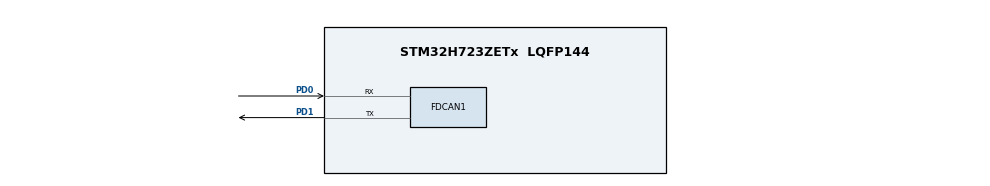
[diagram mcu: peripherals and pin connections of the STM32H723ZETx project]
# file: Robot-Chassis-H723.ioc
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CORTEX_M7.default_mode_Activation=1
FDCAN1.AutoRetransmission=ENABLE
FDCAN1.CalculateBaudRateNominal=999999
FDCAN1.CalculateTimeBitNominal=1000
FDCAN1.CalculateTimeQuantumNominal=45.45454545454546
FDCAN1.NominalPrescaler=5
FDCAN1.NominalTimeSeg1=16
FDCAN1.NominalTimeSeg2=5
FDCAN1.RxFifo1ElmtsNbr=8
FDCAN1.StdFiltersNbr=1
FDCAN1.TxFifoQueueElmtsNbr=8
Mcu.Family=STM32H7
Mcu.Name=STM32H723ZETx
Mcu.Package=LQFP144
NVIC.FDCAN1_IT0_IRQn=true\:0\:0\:false\:false\:true\:true\:true\:true
NVIC.PriorityGroup=NVIC_PRIORITYGROUP_4
PD0.Mode=FDCAN_Activate
PD0.Signal=FDCAN1_RX
PD1.Mode=FDCAN_Activate
PD1.Signal=FDCAN1_TX
PH0-OSC_IN.Mode=HSE-External-Oscillator
PH0-OSC_IN.Signal=RCC_OSC_IN
PH1-OSC_OUT.Mode=HSE-External-Oscillator
PH1-OSC_OUT.Signal=RCC_OSC_OUT
ProjectManager.HeapSize=0x200
ProjectManager.StackSize=0x400
ProjectManager.TargetToolchain=CMake
RCC.ADCFreq_Value=16125000
RCC.APB1Freq_Value=137500000
RCC.APB2Freq_Value=137500000
RCC.APB3Freq_Value=137500000
RCC.APB4Freq_Value=137500000
RCC.CortexFreq_Value=550000000
RCC.D1PPRE=RCC_APB3_DIV2
RCC.D2PPRE1=RCC_APB1_DIV2
RCC.D2PPRE2=RCC_APB2_DIV2
RCC.D3PPRE=RCC_APB4_DIV2
RCC.DIVM1=4
RCC.DIVN1=275
RCC.DIVP1=1
RCC.DIVQ1=5
RCC.HCLKFreq_Value=275000000
RCC.HPRE=RCC_HCLK_DIV2
RCC.HSE_VALUE=8000000
RCC.PLL2FRACN=0
RCC.PLL3FRACN=0
RCC.PLLFRACN=0
RCC.PLLSourceVirtual=RCC_PLLSOURCE_HSE
RCC.SYSCLKFreq_VALUE=550000000
RCC.SYSCLKSource=RCC_SYSCLKSOURCE_PLLCLK
RCC.USBFreq_Value=110000000
VP_MEMORYMAP_VS_MEMORYMAP.Mode=CurAppReg
board=custom

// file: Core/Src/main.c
/* USER CODE BEGIN Header */
/**
  ******************************************************************************
  * @file           : main.c
  * @brief          : Main program body
  ******************************************************************************
  * @attention
  *
  * Copyright (c) 2026 STMicroelectronics.
  * All rights reserved.
  *
  * This software is licensed under terms that can be found in the LICENSE file
  * in the root directory of this software component.
  * If no LICENSE file comes with this software, it is provided AS-IS.
  *
  ******************************************************************************
  */
/* USER CODE END Header */
#include "main.h"
#include "fdcan.h"
#include "gpio.h"

/* USER CODE BEGIN Includes */
#include "can_bus.h"
#include "m3508.h"
#include "pid.h"
/* USER CODE END Includes */

/* USER CODE BEGIN PV */
M3508_t motor1;
M3508_t motor2;
M3508_t motor3;
M3508_t motor4;

PID motor1_pid;
PID motor2_pid;
PID motor3_pid;
PID motor4_pid;

/* USER CODE END PV */

void SystemClock_Config(void);
static void MPU_Config(void);
/* USER CODE BEGIN PFP */
static void Motor_SpeedControl(void);
/* USER CODE END PFP */

/* USER CODE BEGIN 0 */
static void Motor_SpeedControl(void) {
    M3508_SetCurrent(&motor1, (int16_t)PID_Calculate(&motor1_pid, motor1.targetSpeed, motor1.speed));
    M3508_SetCurrent(&motor2, (int16_t)PID_Calculate(&motor2_pid, motor2.targetSpeed, motor2.speed));
    M3508_SetCurrent(&motor3, (int16_t)PID_Calculate(&motor3_pid, motor3.targetSpeed, motor3.speed));
    M3508_SetCurrent(&motor4, (int16_t)PID_Calculate(&motor4_pid, motor4.targetSpeed, motor4.speed));

    M3508_SendCurrent(&motor1, &motor2, &motor3, &motor4);
}
/* USER CODE END 0 */

int main(void)
{

  /* MPU Configuration--------------------------------------------------------*/
  MPU_Config();

  /* MCU Configuration--------------------------------------------------------*/

  /* Reset of all peripherals, Initializes the Flash interface and the Systick. */
  HAL_Init();

  /* Configure the system clock */
  SystemClock_Config();

  /* Initialize all configured peripherals */
  MX_GPIO_Init();
  MX_FDCAN1_Init();
  /* USER CODE BEGIN 2 */
  M3508_Init(&motor1, 0x201);
  M3508_Init(&motor2, 0x202);
  M3508_Init(&motor3, 0x203);
  M3508_Init(&motor4, 0x204);
  PID_Init(&motor1_pid, 0, 0, 0, 0.001f, 0, 3000);
  PID_Init(&motor2_pid, 0, 0, 0, 0.001f, 0, 3000);
  PID_Init(&motor3_pid, 0, 0, 0, 0.001f, 0, 3000);
  PID_Init(&motor4_pid, 0, 0, 0, 0.001f, 0, 3000);
  CAN_Init();
  /* USER CODE END 2 */

  /* Infinite loop */
  while (1)
  {

  }
}

void SystemClock_Config(void)
{
  RCC_OscInitTypeDef RCC_OscInitStruct = {0};
  RCC_ClkInitTypeDef RCC_ClkInitStruct = {0};

  /** Supply configuration update enable
  */
  HAL_PWREx_ConfigSupply(PWR_LDO_SUPPLY);

  /** Configure the main internal regulator output voltage
  */
  __HAL_PWR_VOLTAGESCALING_CONFIG(PWR_REGULATOR_VOLTAGE_SCALE0);

  while(!__HAL_PWR_GET_FLAG(PWR_FLAG_VOSRDY)) {}

  /** Initializes the RCC Oscillators according to the specified parameters
  * in the RCC_OscInitTypeDef structure.
  */
  RCC_OscInitStruct.OscillatorType = RCC_OSCILLATORTYPE_HSE;
  RCC_OscInitStruct.HSEState = RCC_HSE_ON;
  RCC_OscInitStruct.PLL.PLLState = RCC_PLL_ON;
  RCC_OscInitStruct.PLL.PLLSource = RCC_PLLSOURCE_HSE;
  RCC_OscInitStruct.PLL.PLLM = 4;
  RCC_OscInitStruct.PLL.PLLN = 275;
  RCC_OscInitStruct.PLL.PLLP = 1;
  RCC_OscInitStruct.PLL.PLLQ = 5;
  RCC_OscInitStruct.PLL.PLLR = 2;
  RCC_OscInitStruct.PLL.PLLRGE = RCC_PLL1VCIRANGE_1;
  RCC_OscInitStruct.PLL.PLLVCOSEL = RCC_PLL1VCOWIDE;
  RCC_OscInitStruct.PLL.PLLFRACN = 0;
  if (HAL_RCC_OscConfig(&RCC_OscInitStruct) != HAL_OK)
  {
    Error_Handler();
  }

  /** Initializes the CPU, AHB and APB buses clocks
  */
  RCC_ClkInitStruct.ClockType = RCC_CLOCKTYPE_HCLK|RCC_CLOCKTYPE_SYSCLK
                              |RCC_CLOCKTYPE_PCLK1|RCC_CLOCKTYPE_PCLK2
                              |RCC_CLOCKTYPE_D3PCLK1|RCC_CLOCKTYPE_D1PCLK1;
  RCC_ClkInitStruct.SYSCLKSource = RCC_SYSCLKSOURCE_PLLCLK;
  RCC_ClkInitStruct.SYSCLKDivider = RCC_SYSCLK_DIV1;
  RCC_ClkInitStruct.AHBCLKDivider = RCC_HCLK_DIV2;
  RCC_ClkInitStruct.APB3CLKDivider = RCC_APB3_DIV2;
  RCC_ClkInitStruct.APB1CLKDivider = RCC_APB1_DIV2;
  RCC_ClkInitStruct.APB2CLKDivider = RCC_APB2_DIV2;
  RCC_ClkInitStruct.APB4CLKDivider = RCC_APB4_DIV2;

  if (HAL_RCC_ClockConfig(&RCC_ClkInitStruct, FLASH_LATENCY_3) != HAL_OK)
  {
    Error_Handler();
  }
}

 /* MPU Configuration */

void MPU_Config(void)
{
  MPU_Region_InitTypeDef MPU_InitStruct = {0};

  /* Disables the MPU */
  HAL_MPU_Disable();

  /** Initializes and configures the Region and the memory to be protected
  */
  MPU_InitStruct.Enable = MPU_REGION_ENABLE;
  MPU_InitStruct.Number = MPU_REGION_NUMBER0;
  MPU_InitStruct.BaseAddress = 0x0;
  MPU_InitStruct.Size = MPU_REGION_SIZE_4GB;
  MPU_InitStruct.SubRegionDisable = 0x87;
  MPU_InitStruct.TypeExtField = MPU_TEX_LEVEL0;
  MPU_InitStruct.AccessPermission = MPU_REGION_NO_ACCESS;
  MPU_InitStruct.DisableExec = MPU_INSTRUCTION_ACCESS_DISABLE;
  MPU_InitStruct.IsShareable = MPU_ACCESS_SHAREABLE;
  MPU_InitStruct.IsCacheable = MPU_ACCESS_NOT_CACHEABLE;
  MPU_InitStruct.IsBufferable = MPU_ACCESS_NOT_BUFFERABLE;

  HAL_MPU_ConfigRegion(&MPU_InitStruct);
  /* Enables the MPU */
  HAL_MPU_Enable(MPU_PRIVILEGED_DEFAULT);

}

void Error_Handler(void)
{
  __disable_irq();
  while (1)
  {
  }
}
